AUTOSAR XML (schema 4-1-3)
standard types defined: boolean, sint8, uint16, uint32, uint8, boolean_CompuMethod, boolean_DataConstr, sint8_DataConstr, uint16_DataConstr, uint32_DataConstr, uint8_DataConstr, sint16
package /MICROSAR/Dem_swc/DataTypes
  5 x impl type:
    Dem_DebounceResetStatusType: compu {0=DEM_DEBOUNCE_STATUS_FREEZE, 1=DEM_DEBOUNCE_STATUS_RESET}, range raw 0..255, implementation-data-type=ImplementationDataTypes/uint8
    Dem_DTCFormatType: compu {0=DEM_DTC_FORMAT_OBD, 1=DEM_DTC_FORMAT_UDS, 2=DEM_DTC_FORMAT_J1939}, range raw 0..2, implementation-data-type=ImplementationDataTypes/uint8
    Dem_EventStatusType:
      compu {0=DEM_EVENT_STATUS_PASSED, 1=DEM_EVENT_STATUS_FAILED, 2=DEM_EVENT_STATUS_PREPASSED, 3=DEM_EVENT_STATUS_PREFAILED, 4=DEM_EVENT_STATUS_FDC_THRESHOLD_REACHED, 5=DEM_EVENT_STATUS_PASSED_CONDITIONS_NOT_FULFILLED, 6=DEM_EVENT_STATUS_FAILED_CONDITIONS_NOT_FULFILLED, 7=DEM_EVENT_STATUS_PREPASSED_CONDITIONS_NOT_FULFILLED, 8=DEM_EVENT_STATUS_PREFAILED_CONDITIONS_NOT_FULFILLED}
      range raw 0..255
      implementation-data-type=ImplementationDataTypes/uint8
    Dem_MaxDataValueType: category=ARRAY, sw-calibration-access=READ-ONLY
      element Dem_MaxDataValueTypeElement: array-size=14, array-size-semantics=FIXED-SIZE, implementation-data-type=ImplementationDataTypes/uint8
    Dem_UdsStatusByteType:
      compu {mask 1: 1=DEM_UDS_STATUS_TF (bit 0: TestFailed), mask 2: 2=DEM_UDS_STATUS_TFTOC (bit 1: TestFailedThisOperationCycle), mask 4: 4=DEM_UDS_STATUS_PDTC (bit 2: PendingDTC), mask 8: 8=DEM_UDS_STATUS_CDTC (bit 3: ConfirmedDTC), mask 16: 16=DEM_UDS_STATUS_TNCSLC (bit 4: TestNotCompletedSinceLastClear), mask 32: 32=DEM_UDS_STATUS_TFSLC (bit 5: TestFailedSinceLastClear), mask 64: 64=DEM_UDS_STATUS_TNCTOC (bit 6: TestNotCompletedThisOperationCycle), mask 128: 128=DEM_UDS_STATUS_WIR (bit 7: WarningIndicatorRequested)}
      range raw 0..255
      implementation-data-type=ImplementationDataTypes/uint8
package /MICROSAR/Dem_swc/Interfaces
  client server interface DiagnosticMonitor: is-service=true, service-kind=DIAGNOSTIC-EVENT-MANAGER
    11 x operation:
      GetDTCOfEvent: possible-error=[DEM_E_NO_DTC_AVAILABLE, DiagnosticMonitor/E_NOT_OK]
        arg DTCFormat: type=Dem_DTCFormatType, direction=IN, server-argument-impl-policy=USE-ARGUMENT-TYPE
        arg DTCOfEvent: type=uint32, direction=OUT, server-argument-impl-policy=USE-ARGUMENT-TYPE
      GetEventExtendedDataRecordEx: possible-error=[DEM_BUFFER_TOO_SMALL, DEM_NO_SUCH_ELEMENT, DiagnosticMonitor/E_NOT_OK]
        arg RecordNumber: type=ImplementationDataTypes/uint8, direction=IN, server-argument-impl-policy=USE-ARGUMENT-TYPE
        arg DestBuffer: type=Dem_MaxDataValueType, direction=OUT, server-argument-impl-policy=USE-ARGUMENT-TYPE
        arg BufSize: type=ImplementationDataTypes/uint16, direction=INOUT, server-argument-impl-policy=USE-ARGUMENT-TYPE
      GetEventFailed: possible-error=DiagnosticMonitor/E_NOT_OK
        arg EventFailed: type=ImplementationDataTypes/boolean, direction=OUT, server-argument-impl-policy=USE-ARGUMENT-TYPE
      GetEventFreezeFrameDataEx: possible-error=[DEM_BUFFER_TOO_SMALL, DEM_NO_SUCH_ELEMENT, DiagnosticMonitor/E_NOT_OK]
        4 x arg, all with server-argument-impl-policy=USE-ARGUMENT-TYPE:
          RecordNumber: type=ImplementationDataTypes/uint8, direction=IN
          DataId: type=ImplementationDataTypes/uint16, direction=IN
          DestBuffer: type=Dem_MaxDataValueType, direction=OUT
          BufSize: type=ImplementationDataTypes/uint16, direction=INOUT
      GetEventStatus: possible-error=DiagnosticMonitor/E_NOT_OK
        arg UDSStatusByte: type=Dem_UdsStatusByteType, direction=OUT, server-argument-impl-policy=USE-ARGUMENT-TYPE
      GetEventTested: possible-error=DiagnosticMonitor/E_NOT_OK
        arg EventTested: type=ImplementationDataTypes/boolean, direction=OUT, server-argument-impl-policy=USE-ARGUMENT-TYPE
      GetEventUdsStatus: possible-error=DiagnosticMonitor/E_NOT_OK
        arg UDSStatusByte: type=Dem_UdsStatusByteType, direction=OUT, server-argument-impl-policy=USE-ARGUMENT-TYPE
      GetFaultDetectionCounter: possible-error=[DEM_E_NO_FDC_AVAILABLE, DiagnosticMonitor/E_NOT_OK]
        arg FaultDetectionCounter: type=sint8, direction=OUT, server-argument-impl-policy=USE-ARGUMENT-TYPE
      ResetEventDebounceStatus: possible-error=DiagnosticMonitor/E_NOT_OK
        arg DebounceResetStatus: type=Dem_DebounceResetStatusType, direction=IN, server-argument-impl-policy=USE-ARGUMENT-TYPE
      ResetEventStatus: possible-error=DiagnosticMonitor/E_NOT_OK
      SetEventStatus: possible-error=DiagnosticMonitor/E_NOT_OK
        arg EventStatus: type=Dem_EventStatusType, direction=IN, server-argument-impl-policy=USE-ARGUMENT-TYPE
    5 x error:
      DEM_BUFFER_TOO_SMALL: error-code=21
      DEM_E_NO_DTC_AVAILABLE: error-code=10
      DEM_E_NO_FDC_AVAILABLE: error-code=14
      DEM_NO_SUCH_ELEMENT: error-code=48
      E_NOT_OK: error-code=1
  client server interface EnableCondition: is-service=true, service-kind=DIAGNOSTIC-EVENT-MANAGER
    operation SetEnableCondition: possible-error=EnableCondition/E_NOT_OK
      arg ConditionFulfilled: type=ImplementationDataTypes/boolean, direction=IN, server-argument-impl-policy=USE-ARGUMENT-TYPE
    error E_NOT_OK: error-code=1
package /UAES/ASW/ApplicationDataTypes
  app type Fac_q0p001_u16: category=VALUE, sw-calibration-access=READ-WRITE, compu {phys=raw*0.001}, range phys 0..65.535
package /UAES/ASW/CompuMethods
  compu method CM_boolean: 0=FALSE, 1=TRUE
package /UAES/ASW/DataConstrs
  range DC_boolean: raw 0..1
  range DC_sint16: raw -32768..32767
  range DC_uint16: raw 0..65535
  range DC_uint8: raw 0..255
package /UAES/ASW/DataTypeMappingSets
  data type mapping set DTMS_BattU_DD: data-type-map{application-data-type=Fac_q0p001_u16, implementation-data-type=ImplementationDataTypes/uint16}
package /UAES/ASW/PortInterfaces
  client server interface IoHwAb_IoSigAdc
    operation Adc_Get: possible-error=IoHwAb_IoSigAdc/E_NOT_OK
      arg id_u16: type=ImplementationDataTypes/uint16, direction=IN, server-argument-impl-policy=USE-ARGUMENT-TYPE
      arg val_s16: type=sint16, direction=OUT, server-argument-impl-policy=USE-ARGUMENT-TYPE
    operation AdcFac_Get: possible-error=IoHwAb_IoSigAdc/E_NOT_OK
      arg id_u16: type=ImplementationDataTypes/uint16, direction=IN, server-argument-impl-policy=USE-ARGUMENT-TYPE
      arg val_s16: type=sint16, direction=OUT, server-argument-impl-policy=USE-ARGUMENT-TYPE
    operation AdcVRMBatt_Get: possible-error=IoHwAb_IoSigAdc/E_NOT_OK
      arg id_u16: type=ImplementationDataTypes/uint16, direction=IN, server-argument-impl-policy=USE-ARGUMENT-TYPE
      arg val_u8: type=ImplementationDataTypes/uint8, direction=OUT, server-argument-impl-policy=USE-ARGUMENT-TYPE
    error E_NOT_OK: error-code=1
  9 x sender receiver interface:
    BattU_buExcdLrgRng: invalidation-policy{data-element=BattU_buExcdLrgRng/Val, handle-invalid=DONT-INVALIDATE}
      data Val: sw-calibration-access=READ-ONLY, type=ImplementationDataTypes/boolean
    BattU_buExcdSmallRng: invalidation-policy{data-element=BattU_buExcdSmallRng/Val, handle-invalid=DONT-INVALIDATE}
      data Val: sw-calibration-access=READ-ONLY, type=ImplementationDataTypes/boolean
    BattU_bVoltEnbNMDiag: invalidation-policy{data-element=BattU_bVoltEnbNMDiag/Val, handle-invalid=DONT-INVALIDATE}
      data Val: sw-calibration-access=READ-ONLY, type=ImplementationDataTypes/boolean
    BattU_bVoltEnbPinDiag: invalidation-policy{data-element=BattU_bVoltEnbPinDiag/Val, handle-invalid=DONT-INVALIDATE}
      data Val: sw-calibration-access=READ-ONLY, type=ImplementationDataTypes/boolean
    BattU_VrmFac1: invalidation-policy{data-element=BattU_VrmFac1/Val, handle-invalid=DONT-INVALIDATE}
      data Val: sw-calibration-access=READ-ONLY, type=Fac_q0p001_u16
    BattU_VrmFac2: invalidation-policy{data-element=BattU_VrmFac2/Val, handle-invalid=DONT-INVALIDATE}
      data Val: sw-calibration-access=READ-ONLY, type=Fac_q0p001_u16
    BattU_VrmFac3: invalidation-policy{data-element=BattU_VrmFac3/Val, handle-invalid=DONT-INVALIDATE}
      data Val: sw-calibration-access=READ-ONLY, type=Fac_q0p001_u16
    gDiag_u16BatteryVolt_mv: invalidation-policy{data-element=gDiag_u16BatteryVolt_mv/Val, handle-invalid=DONT-INVALIDATE}
      data Val: sw-calibration-access=READ-ONLY, type=ImplementationDataTypes/uint16
    gVRM_u16BatteryVolt_mv: invalidation-policy{data-element=gVRM_u16BatteryVolt_mv/Val, handle-invalid=DONT-INVALIDATE}
      data Val: sw-calibration-access=READ-ONLY, type=ImplementationDataTypes/uint16
package /UAES/ASW/SwComponentTypes
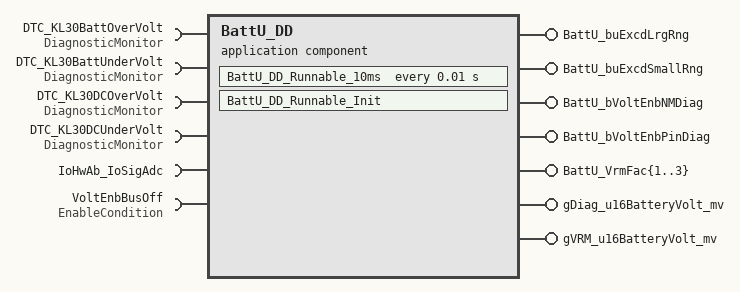
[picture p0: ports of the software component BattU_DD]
  application sw component type BattU_DD
    9 x provide port:
      BattU_buExcdLrgRng: nonqueued-sender-com-spec{data-element=BattU_buExcdLrgRng/Val, init-value=0}, provided-interface=BattU_buExcdLrgRng
      BattU_buExcdSmallRng: nonqueued-sender-com-spec{data-element=BattU_buExcdSmallRng/Val, init-value=0}, provided-interface=BattU_buExcdSmallRng
      BattU_bVoltEnbNMDiag: nonqueued-sender-com-spec{data-element=BattU_bVoltEnbNMDiag/Val, init-value=0}, provided-interface=BattU_bVoltEnbNMDiag
      BattU_bVoltEnbPinDiag: nonqueued-sender-com-spec{data-element=BattU_bVoltEnbPinDiag/Val, init-value=0}, provided-interface=BattU_bVoltEnbPinDiag
      BattU_VrmFac{1..3}: nonqueued-sender-com-spec{data-element=BattU_VrmFac{1..3}/Val, init-value=0}, provided-interface=BattU_VrmFac{1..3}
      gDiag_u16BatteryVolt_mv: nonqueued-sender-com-spec{data-element=gDiag_u16BatteryVolt_mv/Val, init-value=0}, provided-interface=gDiag_u16BatteryVolt_mv
      gVRM_u16BatteryVolt_mv: nonqueued-sender-com-spec{data-element=gVRM_u16BatteryVolt_mv/Val, init-value=0}, provided-interface=gVRM_u16BatteryVolt_mv
    6 x require port:
      DTC_KL30BattOverVolt: required-interface=DiagnosticMonitor
        required-com-specs:
          GetDTCOfEvent
          GetEventExtendedDataRecordEx
          GetEventFailed
          GetEventFreezeFrameDataEx
          GetEventStatus
          GetEventTested
          GetEventUdsStatus
          GetFaultDetectionCounter
          ResetEventDebounceStatus
          ResetEventStatus
          SetEventStatus
      DTC_KL30BattUnderVolt: required-interface=DiagnosticMonitor
        required-com-specs:
          GetDTCOfEvent
          GetEventExtendedDataRecordEx
          GetEventFailed
          GetEventFreezeFrameDataEx
          GetEventStatus
          GetEventTested
          GetEventUdsStatus
          GetFaultDetectionCounter
          ResetEventDebounceStatus
          ResetEventStatus
          SetEventStatus
      DTC_KL30DCOverVolt: required-interface=DiagnosticMonitor
        required-com-specs:
          GetDTCOfEvent
          GetEventExtendedDataRecordEx
          GetEventFailed
          GetEventFreezeFrameDataEx
          GetEventStatus
          GetEventTested
          GetEventUdsStatus
          GetFaultDetectionCounter
          ResetEventDebounceStatus
          ResetEventStatus
          SetEventStatus
      DTC_KL30DCUnderVolt: required-interface=DiagnosticMonitor
        required-com-specs:
          GetDTCOfEvent
          GetEventExtendedDataRecordEx
          GetEventFailed
          GetEventFreezeFrameDataEx
          GetEventStatus
          GetEventTested
          GetEventUdsStatus
          GetFaultDetectionCounter
          ResetEventDebounceStatus
          ResetEventStatus
          SetEventStatus
      IoHwAb_IoSigAdc: required-com-specs=[Adc_Get, AdcFac_Get, AdcVRMBatt_Get], required-interface=IoHwAb_IoSigAdc
      VoltEnbBusOff: client-com-spec=SetEnableCondition, required-interface=EnableCondition
    behavior BattU_DD_InternalBehavior: data-type-mapping=DTMS_BattU_DD
      timing event TMT_BattU_DD_Runnable_10ms: start-on-event=BattU_DD_Runnable_10ms, period=0.01
      init event BattU_DD_InitEvent: start-on-event=BattU_DD_Runnable_Init
      runnable BattU_DD_Runnable_10ms
        data-send-points:
          9 x access:
            SEND_BattU_buExcdLrgRng_Val: accessed-variable=BattU_buExcdLrgRng.Val
            SEND_BattU_buExcdSmallRng_Val: accessed-variable=BattU_buExcdSmallRng.Val
            SEND_BattU_bVoltEnbNMDiag_Val: accessed-variable=BattU_bVoltEnbNMDiag.Val
            SEND_BattU_bVoltEnbPinDiag_Val: accessed-variable=BattU_bVoltEnbPinDiag.Val
            SEND_BattU_VrmFac{1..3}_Val: accessed-variable=BattU_VrmFac{1..3}.Val
            SEND_gDiag_u16BatteryVolt_mv_Val: accessed-variable=gDiag_u16BatteryVolt_mv.Val
            SEND_gVRM_u16BatteryVolt_mv_Val: accessed-variable=gVRM_u16BatteryVolt_mv.Val
        23 x sync call:
          SC_DTC_KL30BattOverVolt_GetEventFailed: operation=DTC_KL30BattOverVolt.GetEventFailed, timeout=1E-06
          SC_DTC_KL30BattOverVolt_GetEventTested: operation=DTC_KL30BattOverVolt.GetEventTested, timeout=1E-06
          SC_DTC_KL30BattOverVolt_ResetEventDebounceStatus: operation=DTC_KL30BattOverVolt.ResetEventDebounceStatus, timeout=1E-06
          SC_DTC_KL30BattOverVolt_ResetEventStatus: operation=DTC_KL30BattOverVolt.ResetEventStatus, timeout=1E-06
          SC_DTC_KL30BattOverVolt_SetEventStatus: operation=DTC_KL30BattOverVolt.SetEventStatus, timeout=1E-06
          SC_DTC_KL30BattUnderVolt_GetEventFailed: operation=DTC_KL30BattUnderVolt.GetEventFailed, timeout=1E-06
          SC_DTC_KL30BattUnderVolt_GetEventTested: operation=DTC_KL30BattUnderVolt.GetEventTested, timeout=1E-06
          SC_DTC_KL30BattUnderVolt_ResetEventDebounceStatus: operation=DTC_KL30BattUnderVolt.ResetEventDebounceStatus, timeout=1E-06
          SC_DTC_KL30BattUnderVolt_ResetEventStatus: operation=DTC_KL30BattUnderVolt.ResetEventStatus, timeout=1E-06
          SC_DTC_KL30BattUnderVolt_SetEventStatus: operation=DTC_KL30BattUnderVolt.SetEventStatus, timeout=1E-06
          SC_DTC_KL30DCOverVolt_GetEventFailed: operation=DTC_KL30DCOverVolt.GetEventFailed, timeout=1E-06
          SC_DTC_KL30DCOverVolt_GetEventStatus: operation=DTC_KL30DCOverVolt.GetEventStatus, timeout=1E-06
          SC_DTC_KL30DCOverVolt_ResetEventDebounceStatus: operation=DTC_KL30DCOverVolt.ResetEventDebounceStatus, timeout=1E-06
          SC_DTC_KL30DCOverVolt_ResetEventStatus: operation=DTC_KL30DCOverVolt.ResetEventStatus, timeout=1E-06
          SC_DTC_KL30DCOverVolt_SetEventStatus: operation=DTC_KL30DCOverVolt.SetEventStatus, timeout=1E-06
          SC_DTC_KL30DCUnderVolt_GetEventFailed: operation=DTC_KL30DCUnderVolt.GetEventFailed, timeout=1E-06
          SC_DTC_KL30DCUnderVolt_GetEventTested: operation=DTC_KL30DCUnderVolt.GetEventTested, timeout=1E-06
          SC_DTC_KL30DCUnderVolt_ResetEventDebounceStatus: operation=DTC_KL30DCUnderVolt.ResetEventDebounceStatus, timeout=1E-06
          SC_DTC_KL30DCUnderVolt_ResetEventStatus: operation=DTC_KL30DCUnderVolt.ResetEventStatus, timeout=1E-06
          SC_DTC_KL30DCUnderVolt_SetEventStatus: operation=DTC_KL30DCUnderVolt.SetEventStatus, timeout=1E-06
          SC_IoHwAb_IoSigAdc_AdcFac_Get: operation=IoHwAb_IoSigAdc.AdcFac_Get, timeout=0
          SC_IoHwAb_IoSigAdc_AdcVRMBatt_Get: operation=IoHwAb_IoSigAdc.AdcVRMBatt_Get, timeout=0
          SC_VoltEnbBusOff_SetEnableCondition: operation=VoltEnbBusOff.SetEnableCondition, timeout=1E-06
      runnable BattU_DD_Runnable_Init
  swc implementation Implementation_BattU_DD: behavior=BattU_DD_InternalBehavior
    code-descriptors:
      code Default: artifact-descriptors=autosar-engineering-object={short-label=Default, category=SWSRC}
package /UAES/ASW/Units
  unit NoUnit: factor-si-to-unit=1, offset-si-to-unit=0
